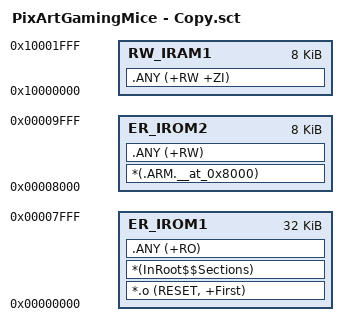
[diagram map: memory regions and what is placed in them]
; *************************************************************
; *** Scatter-Loading Description File generated by uVision ***
; *************************************************************

LR1 0x0
{
  ER_IROM1 0x00000000 0x00008000  {  ; load address = execution address
   *.o (RESET, +First)
   *(InRoot$$Sections)
   .ANY (+RO)
  }
    ER_IROM2 0x00008000 0x2000
    {
        *(.ARM.__at_0x8000)  ; .ARM.__at_0x2000 is selected by the section named
                             ; .ARM.__at_0x2000
							 .ANY (+RW)
    }
  RW_IRAM1 0x10000000 0x00002000  {  ; RW data
   .ANY (+RW +ZI)
  }
}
